# STM32WBA52 register map
File version: 0.1
CPU: CM33 r0p1, little endian, MPU, FPU, 4 interrupt priority bits
Registers are 32-bit, read-write, reset 0x0 unless marked. A register's access mark holds for its fields unless they carry their own. Offsets are from the block's base; [hi:lo] are bit positions; {n}, {i} and the like mark numbered series; <NAME> marks a mode.

## I2C1 — Inter-integrated circuit
Base 0x40005400
Same registers: I2C3 0x46002800, SEC_I2C1 0x50005400, SEC_I2C3 0x56002800
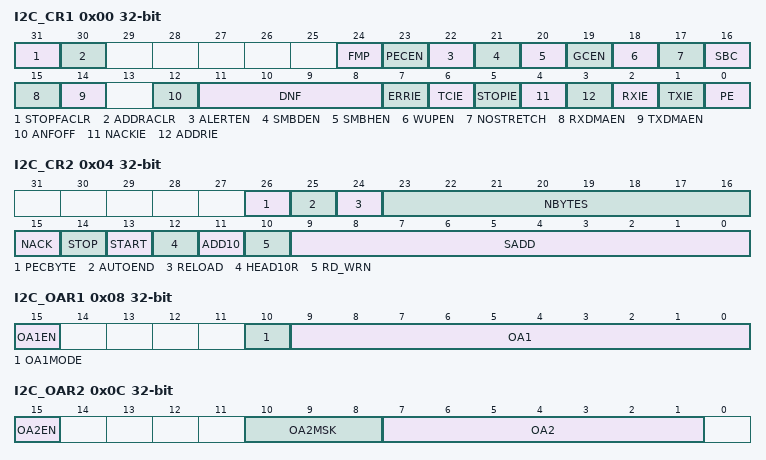
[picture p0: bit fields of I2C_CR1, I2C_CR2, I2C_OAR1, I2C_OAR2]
0x00 I2C_CR1 — I2C control register 1
  [31] STOPFACLR — STOP detection flag (STOPF) automatic clear
    0=STOPF flag is set by hardware and cleared by software by setting STOPCF bit; 1=STOPF flag remains cleared by hardware. This mode can be used in NOSTRETCH slave mode, to avoid the overrun error if the STOPF flag is not cleared before next data transmission. This allows a slave data management by DMA only, without any interrupt from peripheral.
  [30] ADDRACLR — Address match flag (ADDR) automatic clear
    0=ADDR flag is set by hardware and cleared by software by setting ADDRCF bit; 1=ADDR flag remains cleared by hardware. This mode can be used in slave mode, to avoid the ADDR clock stretching if the I2C enables only one slave address. This allows a slave data management by DMA only, without any interrupt from peripheral.
  [24] FMP — Fast-mode Plus 20 mA drive enable
    0=20 mA I/O drive disabled; 1=20 mA I/O drive enabled
  [23] PECEN — PEC enable Note: If the SMBus feature is not supported, this bit is reserved and forced by hardware to ‘0’. Refer to Section 52.3: FMPI2C implementation.
    0=PEC calculation disabled; 1=PEC calculation enabled
  [22] ALERTEN — SMBus alert enable Note: When ALERTEN=0, the SMBA pin can be used as a standard GPIO. Note: If the SMBus feature is not supported, this bit is reserved and forced by hardware to ‘0’. Refer to Section 52.3: FMPI2C implementation.
    0=The SMBus alert pin (SMBA) is not supported in host mode (SMBHEN=1). In device mode (SMBHEN=0), the SMBA pin is released and the Alert Response Address header is disabled (0001100x followed by NACK).; 1=The SMBus alert pin is supported in host mode (SMBHEN=1). In device mode (SMBHEN=0), the SMBA pin is driven low and the Alert Response Address header is enabled (0001100x followed by ACK).
  [21] SMBDEN — SMBus device default address enable Note: If the SMBus feature is not supported, this bit is reserved and forced by hardware to ‘0’. Refer to Section 52.3: FMPI2C implementation.
    0=Device default address disabled. Address 0b1100001x is NACKed.; 1=Device default address enabled. Address 0b1100001x is ACKed.
  [20] SMBHEN — SMBus host address enable Note: If the SMBus feature is not supported, this bit is reserved and forced by hardware to ‘0’. Refer to Section 52.3: FMPI2C implementation.
    0=Host address disabled. Address 0b0001000x is NACKed.; 1=Host address enabled. Address 0b0001000x is ACKed.
  [19] GCEN — General call enable
    0=General call disabled. Address 0b00000000 is NACKed.; 1=General call enabled. Address 0b00000000 is ACKed.
  [18] WUPEN — Wakeup from Stop mode enable Note: If the Wakeup from Stop mode feature is not supported, this bit is reserved and forced by hardware to ‘0’. Refer to Section 52.3: FMPI2C implementation. Note: WUPEN can be set only when DNF = ‘0000’
    0=Wakeup from Stop mode disable; 1=Wakeup from Stop mode enable
  [17] NOSTRETCH — Clock stretching disable This bit is used to disable clock stretching in slave mode. It must be kept cleared in master mode. Note: This bit can only be programmed when the I2C is disabled (PE = 0).
    0=Clock stretching enabled; 1=Clock stretching disabled
  [16] SBC — Slave byte control This bit is used to enable hardware byte control in slave mode.
    0=Slave byte control disabled; 1=Slave byte control enabled
  [15] RXDMAEN — DMA reception requests enable
    0=DMA mode disabled for reception; 1=DMA mode enabled for reception
  [14] TXDMAEN — DMA transmission requests enable
    0=DMA mode disabled for transmission; 1=DMA mode enabled for transmission
  [12] ANFOFF — Analog noise filter OFF Note: This bit can only be programmed when the I2C is disabled (PE = 0).
    0=Analog noise filter enabled; 1=Analog noise filter disabled
  [11:8] DNF — Digital noise filter These bits are used to configure the digital noise filter on SDA and SCL input. The digital filter, filters spikes with a length of up to DNF[3:0] * t<sub>I2CCLK</sub> <sub>...</sub> Note: If the analog filter is also enabled, the digital filter is added to the analog filter. Note: This filter can only be programmed when the I2C is disabled (PE = 0).
    0=Digital filter disabled; 1=Digital filter enabled and filtering capability up to 1 t<sub>I2CCLK</sub>; 15=digital filter enabled and filtering capability up to15 t<sub>I2CCLK</sub>
  [7] ERRIE — Error interrupts enable Note: Any of these errors generate an interrupt: Note: Arbitration Loss (ARLO) Note: Bus Error detection (BERR) Note: Overrun/Underrun (OVR) Note: Timeout detection (TIMEOUT) Note: PEC error detection (PECERR) Note: Alert pin event detection (ALERT)
    0=Error detection interrupts disabled; 1=Error detection interrupts enabled
  [6] TCIE — Transfer Complete interrupt enable Note: Any of these events generate an interrupt: Note: Transfer Complete (TC) Note: Transfer Complete Reload (TCR)
    0=Transfer Complete interrupt disabled; 1=Transfer Complete interrupt enabled
  [5] STOPIE — Stop detection Interrupt enable
    0=Stop detection (STOPF) interrupt disabled; 1=Stop detection (STOPF) interrupt enabled
  [4] NACKIE — Not acknowledge received Interrupt enable
    0=Not acknowledge (NACKF) received interrupts disabled; 1=Not acknowledge (NACKF) received interrupts enabled
  [3] ADDRIE — Address match Interrupt enable (slave only)
    0=Address match (ADDR) interrupts disabled; 1=Address match (ADDR) interrupts enabled
  [2] RXIE — RX Interrupt enable
    0=Receive (RXNE) interrupt disabled; 1=Receive (RXNE) interrupt enabled
  [1] TXIE — TX Interrupt enable
    0=Transmit (TXIS) interrupt disabled; 1=Transmit (TXIS) interrupt enabled
  [0] PE — Peripheral enable Note: When PE = 0, the I2C SCL and SDA lines are released. Internal state machines and status bits are put back to their reset value. When cleared, PE must be kept low for at least 3 APB clock cycles.
    0=Peripheral disable; 1=Peripheral enable
0x04 I2C_CR2 — I2C control register 2
  [26] PECBYTE — Packet error checking byte This bit is set by software, and cleared by hardware when the PEC is transferred, or when a STOP condition or an Address matched is received, also when PE = 0. Note: Writing ‘0’ to this bit has no effect. Note: This bit has no effect when RELOAD is set. Note: This bit has no effect is slave mode when SBC=0. Note: If the SMBus feature is not supported, this bit is reserved and forced by hardware to ‘0’. Refer to Section 52.3: FMPI2C implementation.
    0=No PEC transfer; 1=PEC transmission/reception is requested
  [25] AUTOEND — Automatic end mode (master mode) This bit is set and cleared by software. Note: This bit has no effect in slave mode or when the RELOAD bit is set.
    0=software end mode: TC flag is set when NBYTES data are transferred, stretching SCL low; 1=Automatic end mode: a STOP condition is automatically sent when NBYTES data are transferred
  [24] RELOAD — NBYTES reload mode This bit is set and cleared by software.
    0=The transfer is completed after the NBYTES data transfer (STOP or RESTART follows); 1=The transfer is not completed after the NBYTES data transfer (NBYTES is reloaded). TCR flag is set when NBYTES data are transferred, stretching SCL low.
  [23:16] NBYTES — Number of bytes The number of bytes to be transmitted/received is programmed there. This field is don’t care in slave mode with SBC=0. Note: Changing these bits when the START bit is set is not allowed.
  [15] NACK — NACK generation (slave mode) The bit is set by software, cleared by hardware when the NACK is sent, or when a STOP condition or an Address matched is received, or when PE = 0. Note: Writing ‘0’ to this bit has no effect. Note: This bit is used in slave mode only: in master receiver mode, NACK is automatically generated after last byte preceding STOP or RESTART condition, whatever the NACK bit value. Note: When an overrun occurs in slave receiver NOSTRETCH mode, a NACK is automatically generated whatever the NACK bit value. Note: When hardware PEC checking is enabled (PECBYTE=1), the PEC acknowledge value does not depend on the NACK value.
    0=an ACK is sent after current received byte; 1=a NACK is sent after current received byte
  [14] STOP — Stop generation (master mode) The bit is set by software, cleared by hardware when a STOP condition is detected, or when PE = 0. In Master Mode: Note: Writing ‘0’ to this bit has no effect.
    0=No Stop generation; 1=Stop generation after current byte transfer
  [13] START — Start generation This bit is set by software, and cleared by hardware after the Start followed by the address sequence is sent, by an arbitration loss, by an address matched in slave mode, by a timeout error detection, or when PE = 0. If the I2C is already in master mode with AUTOEND = 0, setting this bit generates a Repeated Start condition when RELOAD=0, after the end of the NBYTES transfer. Otherwise setting this bit generates a START condition once the bus is free. Note: Writing ‘0’ to this bit has no effect. Note: The START bit can be set even if the bus is BUSY or I2C is in slave mode. Note: This bit has no effect when RELOAD is set.
    0=No Start generation; 1=Restart/Start generation:
  [12] HEAD10R — 10-bit address header only read direction (master receiver mode) Note: Changing this bit when the START bit is set is not allowed.
    0=The master sends the complete 10 bit slave address read sequence: Start + 2 bytes 10bit address in write direction + Restart + 1st 7 bits of the 10 bit address in read direction; 1=The master only sends the 1st 7 bits of the 10 bit address, followed by Read direction
  [11] ADD10 — 10-bit addressing mode (master mode) Note: Changing this bit when the START bit is set is not allowed.
    0=The master operates in 7-bit addressing mode,; 1=The master operates in 10-bit addressing mode
  [10] RD_WRN — Transfer direction (master mode) Note: Changing this bit when the START bit is set is not allowed.
    0=Master requests a write transfer; 1=Master requests a read transfer
  [9:0] SADD — Slave address (master mode) In 7-bit addressing mode (ADD10 = 0): SADD[7:1] should be written with the 7-bit slave address to be sent. The bits SADD[9], SADD[8] and SADD[0] are don't care. In 10-bit addressing mode (ADD10 = 1): SADD[9:0] should be written with the 10-bit slave address to be sent. Note: Changing these bits when the START bit is set is not allowed.
0x08 I2C_OAR1 — I2C own address 1 register
  [15] OA1EN — Own Address 1 enable
    0=Own address 1 disabled. The received slave address OA1 is NACKed.; 1=Own address 1 enabled. The received slave address OA1 is ACKed.
  [10] OA1MODE — Own Address 1 10-bit mode Note: This bit can be written only when OA1EN=0.
    0=Own address 1 is a 7-bit address; 1=Own address 1 is a 10-bit address
  [9:0] OA1 — Interface own slave address 7-bit addressing mode: OA1[7:1] contains the 7-bit own slave address. The bits OA1[9], OA1[8] and OA1[0] are don't care. 10-bit addressing mode: OA1[9:0] contains the 10-bit own slave address. Note: These bits can be written only when OA1EN=0.
0x0C I2C_OAR2 — I2C own address 2 register
  [15] OA2EN — Own Address 2 enable
    0=Own address 2 disabled. The received slave address OA2 is NACKed.; 1=Own address 2 enabled. The received slave address OA2 is ACKed.
  [10:8] OA2MSK — Own Address 2 masks Note: These bits can be written only when OA2EN=0. Note: As soon as OA2MSK is not equal to 0, the reserved I2C addresses (0b0000xxx and 0b1111xxx) are not acknowledged even if the comparison matches.
    0=No mask; 1=OA2[1] is masked and don’t care. Only OA2[7:2] are compared.; {v}=OA2[{v}:1] are masked and don’t care. Only OA2[7:{v+1}] are compared. (v=2..5); 6=OA2[6:1] are masked and don’t care. Only OA2[7] is compared.; 7=OA2[7:1] are masked and don’t care. No comparison is done, and all (except reserved) 7-bit received addresses are acknowledged.
  [7:1] OA2 — Interface address 7-bit addressing mode: 7-bit address Note: These bits can be written only when OA2EN=0.
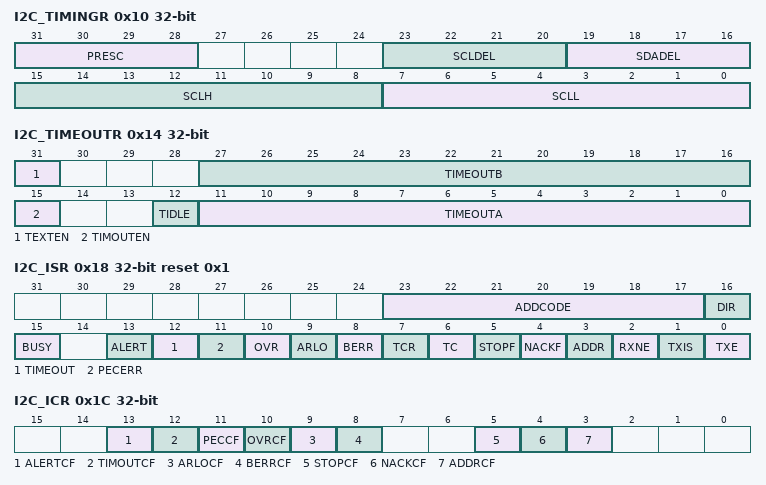
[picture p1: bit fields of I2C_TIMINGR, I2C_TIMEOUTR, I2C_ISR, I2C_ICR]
0x10 I2C_TIMINGR — I2C timing register
  [31:28] PRESC — Timing prescaler This field is used to prescale i2c_ker_ck in order to generate the clock period t<sub>PRESC </sub>used for data setup and hold counters (refer to FMPI2C timings on page 1928) and for SCL high and low level counters (refer to FMPI2C master initialization on page 1951). t<sub>PRESC </sub>= (PRESC+1) x t<sub>I2CCLK</sub>
  [23:20] SCLDEL — Data setup time This field is used to generate a delay t<sub>SCLDEL </sub>between SDA edge and SCL rising edge. In master mode and in slave mode with NOSTRETCH = 0, the SCL line is stretched low during t<sub>SCLDEL</sub>. t<sub>SCLDEL </sub>= (SCLDEL+1) x t<sub>PRESC</sub> Note: t<sub>SCLDEL</sub> is used to generate t<sub>SU:DAT </sub>timing.
  [19:16] SDADEL — Data hold time This field is used to generate the delay t<sub>SDADEL </sub>between SCL falling edge and SDA edge. In master mode and in slave mode with NOSTRETCH = 0, the SCL line is stretched low during t<sub>SDADEL</sub>. t<sub>SDADEL</sub>= SDADEL x t<sub>PRESC</sub> Note: SDADEL is used to generate t<sub>HD:DAT </sub>timing.
  [15:8] SCLH — SCL high period (master mode) This field is used to generate the SCL high period in master mode. t<sub>SCLH </sub>= (SCLH+1) x t<sub>PRESC</sub> Note: SCLH is also used to generate t<sub>SU:STO </sub>and t<sub>HD:STA </sub>timing.
  [7:0] SCLL — SCL low period (master mode) This field is used to generate the SCL low period in master mode. t<sub>SCLL </sub>= (SCLL+1) x t<sub>PRESC</sub> Note: SCLL is also used to generate t<sub>BUF </sub>and t<sub>SU:STA </sub>timings.
0x14 I2C_TIMEOUTR — I2C timeout register
  [31] TEXTEN — Extended clock timeout enable
    0=Extended clock timeout detection is disabled; 1=Extended clock timeout detection is enabled. When a cumulative SCL stretch for more than t<sub>LOW:EXT </sub>is done by the I2C interface, a timeout error is detected (TIMEOUT=1).
  [27:16] TIMEOUTB — Bus timeout B This field is used to configure the cumulative clock extension timeout: In master mode, the master cumulative clock low extend time (t<sub>LOW:MEXT</sub>) is detected In slave mode, the slave cumulative clock low extend time (t<sub>LOW:SEXT</sub>) is detected t<sub>LOW:EXT</sub>= (TIMEOUTB+1) x 2048 x t<sub>I2CCLK</sub> Note: These bits can be written only when TEXTEN=0.
  [15] TIMOUTEN — Clock timeout enable
    0=SCL timeout detection is disabled; 1=SCL timeout detection is enabled: when SCL is low for more than t<sub>TIMEOUT</sub> (TIDLE=0) or high for more than t<sub>IDLE </sub>(TIDLE=1), a timeout error is detected (TIMEOUT=1)
  [12] TIDLE — Idle clock timeout detection Note: This bit can be written only when TIMOUTEN=0.
    0=TIMEOUTA is used to detect SCL low timeout; 1=TIMEOUTA is used to detect both SCL and SDA high timeout (bus idle condition)
  [11:0] TIMEOUTA — Bus Timeout A This field is used to configure: The SCL low timeout condition t<sub>TIMEOUT</sub> when TIDLE=0 t<sub>TIMEOUT</sub>= (TIMEOUTA+1) x 2048 x t<sub>I2CCLK</sub> The bus idle condition (both SCL and SDA high) when TIDLE=1 t<sub>IDLE</sub>= (TIMEOUTA+1) x 4 x t<sub>I2CCLK</sub> Note: These bits can be written only when TIMOUTEN=0.
0x18 I2C_ISR access per field reset 0x1 — I2C interrupt and status register
  [23:17] ADDCODE ro — Address match code (Slave mode) These bits are updated with the received address when an address match event occurs (ADDR = 1). In the case of a 10-bit address, ADDCODE provides the 10-bit header followed by the 2 MSBs of the address.
  [16] DIR ro — Transfer direction (Slave mode) This flag is updated when an address match event occurs (ADDR = 1).
    0=Write transfer, slave enters receiver mode; 1=Read transfer, slave enters transmitter mode
  [15] BUSY ro — Bus busy This flag indicates that a communication is in progress on the bus. It is set by hardware when a START condition is detected. It is cleared by hardware when a STOP condition is detected, or when PE = 0.
  [13] ALERT ro — SMBus alert This flag is set by hardware when SMBHEN=1 (SMBus host configuration), ALERTEN=1 and a SMBALERT event (falling edge) is detected on SMBA pin. It is cleared by software by setting the ALERTCF bit. Note: This bit is cleared by hardware when PE = 0. Note: If the SMBus feature is not supported, this bit is reserved and forced by hardware to ‘0’. Refer to Section 52.3: FMPI2C implementation.
  [12] TIMEOUT ro — Timeout or t<sub>LOW</sub> detection flag This flag is set by hardware when a timeout or extended clock timeout occurred. It is cleared by software by setting the TIMEOUTCF bit. Note: This bit is cleared by hardware when PE = 0. Note: If the SMBus feature is not supported, this bit is reserved and forced by hardware to ‘0’. Refer to Section 52.3: FMPI2C implementation.
  [11] PECERR ro — PEC Error in reception This flag is set by hardware when the received PEC does not match with the PEC register content. A NACK is automatically sent after the wrong PEC reception. It is cleared by software by setting the PECCF bit. Note: This bit is cleared by hardware when PE = 0. Note: If the SMBus feature is not supported, this bit is reserved and forced by hardware to ‘0’. Refer to Section 52.3: FMPI2C implementation.
  [10] OVR ro — Overrun/Underrun (slave mode) This flag is set by hardware in slave mode with NOSTRETCH = 1, when an overrun/underrun error occurs. It is cleared by software by setting the OVRCF bit. Note: This bit is cleared by hardware when PE = 0.
  [9] ARLO ro — Arbitration lost This flag is set by hardware in case of arbitration loss. It is cleared by software by setting the ARLOCF bit. Note: This bit is cleared by hardware when PE = 0.
  [8] BERR ro — Bus error This flag is set by hardware when a misplaced Start or STOP condition is detected whereas the peripheral is involved in the transfer. The flag is not set during the address phase in slave mode. It is cleared by software by setting BERRCF bit. Note: This bit is cleared by hardware when PE = 0.
  [7] TCR ro — Transfer Complete Reload This flag is set by hardware when RELOAD=1 and NBYTES data have been transferred. It is cleared by software when NBYTES is written to a non-zero value. Note: This bit is cleared by hardware when PE = 0. Note: This flag is only for master mode, or for slave mode when the SBC bit is set.
  [6] TC ro — Transfer Complete (master mode) This flag is set by hardware when RELOAD=0, AUTOEND=0 and NBYTES data have been transferred. It is cleared by software when START bit or STOP bit is set. Note: This bit is cleared by hardware when PE = 0.
  [5] STOPF ro — Stop detection flag This flag is set by hardware when a STOP condition is detected on the bus and the peripheral is involved in this transfer: either as a master, provided that the STOP condition is generated by the peripheral. or as a slave, provided that the peripheral has been addressed previously during this transfer. It is cleared by software by setting the STOPCF bit. Note: This bit is cleared by hardware when PE = 0.
  [4] NACKF ro — Not Acknowledge received flag This flag is set by hardware when a NACK is received after a byte transmission. It is cleared by software by setting the NACKCF bit. Note: This bit is cleared by hardware when PE = 0.
  [3] ADDR ro — Address matched (slave mode) This bit is set by hardware as soon as the received slave address matched with one of the enabled slave addresses. It is cleared by software by setting ADDRCF bit. Note: This bit is cleared by hardware when PE = 0.
  [2] RXNE ro — Receive data register not empty (receivers) This bit is set by hardware when the received data is copied into the I2C_RXDR register, and is ready to be read. It is cleared when I2C_RXDR is read. Note: This bit is cleared by hardware when PE = 0.
  [1] TXIS rw — Transmit interrupt status (transmitters) This bit is set by hardware when the I2C_TXDR register is empty and the data to be transmitted must be written in the I2C_TXDR register. It is cleared when the next data to be sent is written in the I2C_TXDR register. This bit can be written to ‘1’ by software when NOSTRETCH = 1 only, in order to generate a TXIS event (interrupt if TXIE=1 or DMA request if TXDMAEN = 1). Note: This bit is cleared by hardware when PE = 0.
  [0] TXE rw — Transmit data register empty (transmitters) This bit is set by hardware when the I2C_TXDR register is empty. It is cleared when the next data to be sent is written in the I2C_TXDR register. This bit can be written to ‘1’ by software in order to flush the transmit data register I2C_TXDR. Note: This bit is set by hardware when PE = 0.
0x1C I2C_ICR wo — I2C interrupt clear register
  [13] ALERTCF — Alert flag clear Writing 1 to this bit clears the ALERT flag in the I2C_ISR register. Note: If the SMBus feature is not supported, this bit is reserved and forced by hardware to ‘0’. Refer to Section 52.3: FMPI2C implementation.
  [12] TIMOUTCF — Timeout detection flag clear Writing 1 to this bit clears the TIMEOUT flag in the I2C_ISR register. Note: If the SMBus feature is not supported, this bit is reserved and forced by hardware to ‘0’. Refer to Section 52.3: FMPI2C implementation.
  [11] PECCF — PEC Error flag clear Writing 1 to this bit clears the PECERR flag in the I2C_ISR register. Note: If the SMBus feature is not supported, this bit is reserved and forced by hardware to ‘0’. Refer to Section 52.3: FMPI2C implementation.
  [10] OVRCF — Overrun/Underrun flag clear Writing 1 to this bit clears the OVR flag in the I2C_ISR register.
  [9] ARLOCF — Arbitration lost flag clear Writing 1 to this bit clears the ARLO flag in the I2C_ISR register.
  [8] BERRCF — Bus error flag clear Writing 1 to this bit clears the BERRF flag in the I2C_ISR register.
  [5] STOPCF — STOP detection flag clear Writing 1 to this bit clears the STOPF flag in the I2C_ISR register.
  [4] NACKCF — Not Acknowledge flag clear Writing 1 to this bit clears the NACKF flag in I2C_ISR register.
  [3] ADDRCF — Address matched flag clear Writing 1 to this bit clears the ADDR flag in the I2C_ISR register. Writing 1 to this bit also clears the START bit in the I2C_CR2 register.
0x20 I2C_PECR ro — I2C PEC register
  [7:0] PEC — Packet error checking register This field contains the internal PEC when PECEN=1. The PEC is cleared by hardware when PE = 0.
0x24 I2C_RXDR ro — I2C receive data register
  [7:0] RXDATA — 8-bit receive data Data byte received from the I<sup>2</sup>C bus
0x28 I2C_TXDR — I2C transmit data register
  [7:0] TXDATA — 8-bit transmit data Data byte to be transmitted to the I<sup>2</sup>C bus Note: These bits can be written only when TXE = 1.
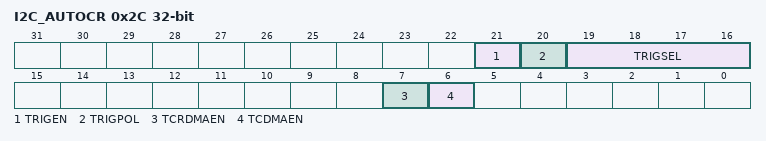
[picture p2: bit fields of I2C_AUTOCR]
0x2C I2C_AUTOCR — I2C Autonomous mode control register
  [21] TRIGEN — Trigger enable When a trigger is detected, a START condition is sent and the transfer is launched as defined in I2C_CR2.
    0=Trigger disabled; 1=Trigger enabled
  [20] TRIGPOL — Trigger polarity Note: This bit can be written only when PE = 0
    0=Trigger active on rising edge; 1=Trigger active on falling edge
  [19:16] TRIGSEL — Trigger selection (refer to Section 52.4.3: FMPI2C pins and internal signals I2C interconnections tables). ... Note: This bit can be written only when PE = 0
    0=i2c_trg0 selected; 1=i2c_trg1 selected; 15=i2c_trg15 selected
  [7] TCRDMAEN — DMA request enable on Transfer Complete Reload event
    0=DMA request not generated on Transfer Complete Reload event; 1=DMA request generated on Transfer Complete Reload event
  [6] TCDMAEN — DMA request enable on Transfer Complete event
    0=DMA request not generated on Transfer Complete event; 1=DMA request generated on Transfer Complete event
